# CM33 register map
Registers are 32-bit, read-write, reset 0x0 unless marked. A register's access mark holds for its fields unless they carry their own. Offsets are from the block's base; [hi:lo] are bit positions; {n}, {i} and the like mark numbered series; 'fields as' and 'values as' point back to an identical list.

## CMO — Cache Maintenance Operations
Base 0xE000EF50
0x00 Instruction Cache Invalidate All to PoU wo — Invalidate all instruction caches to PoU
  [31:0] Ignored — The value written to this field is ignored. Ignored
0x08 Instruction Cache line Invalidate by Address to PoU wo — Invalidate instruction cache line by address to PoU
  [31:0] ADDRESS — Address. Writing to this field initiates the maintenance operation for the address written
0x0C Data Cache line Invalidate by Address to PoC wo — Invalidate data or unified cache line by address to PoC
  [31:0] ADDRESS — Address. Writing to this field initiates the maintenance operation for the address written
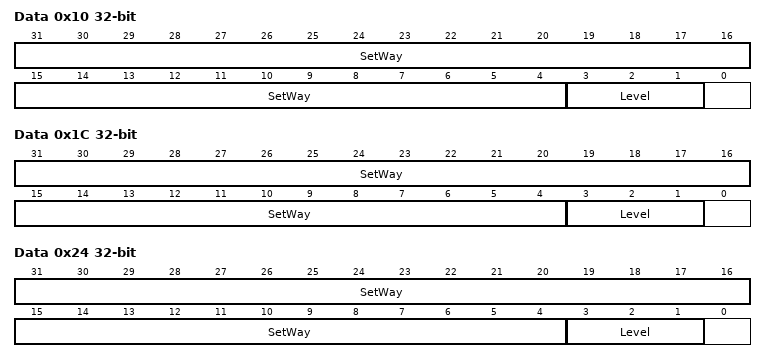
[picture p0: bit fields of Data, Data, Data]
0x10 Data Cache line Invalidate by Set/Way wo — Invalidate data or unified cache line by set/way
  [31:4] SetWay — Cache set/way. Contains two fields: Way, bits[31:32-A], the number of the way to operate on
  [3:1] Level — Cache level. Cache level to operate on, minus 1
0x14 Data Cache line Clean by address to PoU wo — Clean data or unified cache line by address to PoU
  fields as Data
0x18 Data Cache line Clean by Address to PoC wo — Clean data or unified cache line by address to PoC
  fields as Data
0x1C Data Cache Clean line by Set/Way wo — Clean data or unified cache line by set/way
  [31:4] SetWay — Cache set/way. Contains two fields: Way, bits [31:32-A], the number of the way to operate on
  [3:1] Level — Cache level. Cache level to operate on, minus 1
0x20 Data Cache line Clean and Invalidate by Address to PoC wo — Clean and invalidate data or unified cache line by address to PoC
  fields as Data
0x24 Data Cache line Clean and Invalidate by Set/Way wo — Clean and invalidate data or unified cache line by set/way
  [31:4] SetWay — Cache set/way. Contains two fields: Way, bits[31:32-A], the number of the way to operate on
  [3:1] Level — Cache level. Cache level to operate on, minus 1
0x28 Branch Predictor Invalidate All wo — Invalidate all entries from branch predictors
  [31:0] Ignored — Ignored. The value written to this field is ignored

## MPU — Memory Protection Unit (PMSAv8)
Base 0xE000ED90
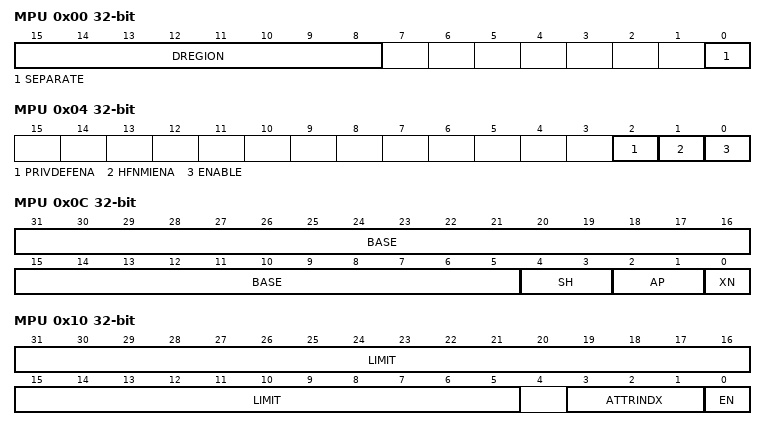
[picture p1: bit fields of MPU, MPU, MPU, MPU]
0x00 MPU Type Register ro reset not defined — How many regions the MPU supports
  [15:8] DREGION — Number of regions supported by the MPU
  [0] SEPARATE — Separate instruction and data regions: 0 on Armv8-M
0x04 MPU Control Register — Enables the MPU, the system address map as background region for privileged accesses, and the MPU for priorities below 0
  [2] PRIVDEFENA — Privileged default enable: the system address map for privileged accesses outside every region
  [1] HFNMIENA — The MPU also for HardFault, NMI and FAULTMASK = 1
  [0] ENABLE — Enables the MPU
0x08 MPU Region Number Register reset not defined — The region MPU_RBAR and MPU_RLAR access
  [7:0] REGION — The region accessed by MPU_RBAR and MPU_RLAR
0x0C MPU Region Base Address Register reset not defined — Base address and attributes of the region MPU_RNR selects
  [31:5] BASE — Bits 31:5 of the region's inclusive lower limit (the base, zero-extended)
  [4:3] SH — Shareability of Normal memory: 0b00 non-shareable, 0b10 outer, 0b11 inner
  [2:1] AP — Access permissions: 0b00 read/write privileged only, 0b01 read/write any, 0b10 read-only privileged only, 0b11 read-only any
  [0] XN — Execute never
0x10 MPU Region Limit Address Register (reset mask 0x1) — Limit address, attribute index and enable of the region MPU_RNR selects
  [31:5] LIMIT — Bits 31:5 of the region's inclusive upper limit (postfixed with 0x1F)
  [3:1] ATTRINDX — Which MPU_MAIR0/1 attribute the region takes
  [0] EN — Region enable
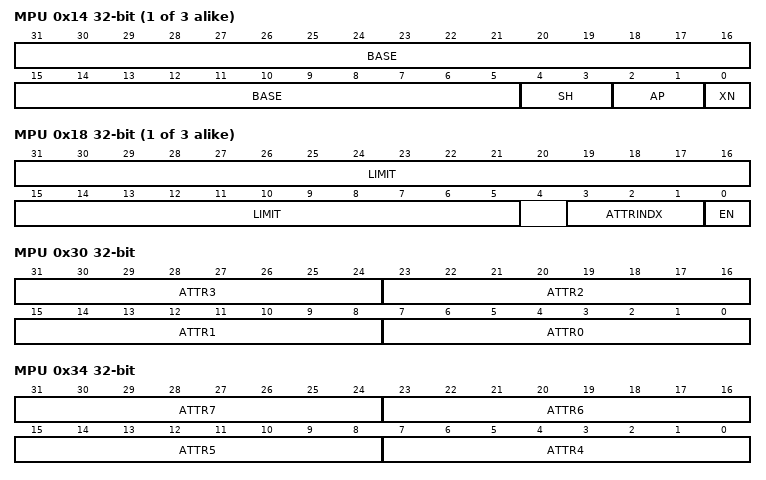
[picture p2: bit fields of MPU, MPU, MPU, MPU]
{0xC+8i} MPU Region Base Address Register Alias {i} reset not defined (i=1..3) — MPU_RBAR of region MPU_RNR[7:2]:{i}
  [31:5] BASE — Bits 31:5 of the region's inclusive lower limit (the base, zero-extended)
  [4:3] SH — Shareability of Normal memory: 0b00 non-shareable, 0b10 outer, 0b11 inner
  [2:1] AP — Access permissions: 0b00 read/write privileged only, 0b01 read/write any, 0b10 read-only privileged only, 0b11 read-only any
  [0] XN — Execute never
{0x10+8i} MPU Region Limit Address Register Alias {i} (reset mask 0x1) (i=1..3) — MPU_RLAR of region MPU_RNR[7:2]:{i}
  [31:5] LIMIT — Bits 31:5 of the region's inclusive upper limit (postfixed with 0x1F)
  [3:1] ATTRINDX — Which MPU_MAIR0/1 attribute the region takes
  [0] EN — Region enable
0x30 MPU Memory Attribute Indirection Register 0 reset not defined — Memory attributes for AttrIndx 0..3
  [8n+7:8n] ATTR{n} (n=0..3) — Memory attributes of the regions with AttrIndx {n}
0x34 MPU Memory Attribute Indirection Register 1 reset not defined — Memory attributes for AttrIndx 4..7
  [8n-25:8n-32] ATTR{n} (n=4..7) — Memory attributes of the regions with AttrIndx {n}
